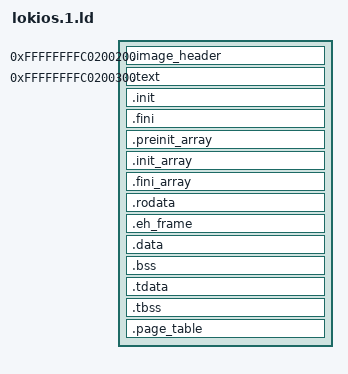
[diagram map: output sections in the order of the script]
SECTIONS
{
    /* This value should match the _kernel_base value in lokios.0.ld. */
    _phys_addr = 0x00200200;
    _virt_addr = 0xFFFFFFFFC0000000 + _phys_addr;
    . = _virt_addr;
    .image_header :
    {
        LONG(_num_sectors)
        LONG(_page_table)
    }

    . = _virt_addr + 0x100;
    .text :
    {
        *lokios.1/entry.o(.text)
        *crtbeginS.o(.text)
        *lokios.1/init.o(.text)
        *(.text)
        *crtendS.o(.text)
    }

    .init :
    {
        *lokios.1/crti.o(.init)
        KEEP (*(SORT_NONE(.init)))
        *lokios.1/crtn.o(.init)
    }

    .fini :
    {
        *lokios.1/crti.o(.fini)
        KEEP (*(SORT_NONE(.fini)))
        *lokios.1/crtn.o(.fini)
    }

    .preinit_array :
    {
        PROVIDE_HIDDEN (__preinit_array_start = .);
        KEEP (*(.preinit_array))
        PROVIDE_HIDDEN (__preinit_array_end = .);
    }

    .init_array :
    {
        PROVIDE_HIDDEN (__init_array_start = .);
        KEEP (*(SORT_BY_INIT_PRIORITY(.init_array.*) \
                SORT_BY_INIT_PRIORITY(.ctors.*)))
        KEEP (*(.init_array \
                EXCLUDE_FILE (*crtbegin.o *crtbegin?.o *crtend.o *crtend?.o ) \
                .ctors))
        PROVIDE_HIDDEN (__init_array_end = .);
    }

    .fini_array :
    {
        PROVIDE_HIDDEN (__fini_array_start = .);
        KEEP (*(SORT_BY_INIT_PRIORITY(.fini_array.*) \
                SORT_BY_INIT_PRIORITY(.dtors.*)))
        KEEP (*(.fini_array \
                EXCLUDE_FILE (*crtbegin.o *crtbegin?.o *crtend.o *crtend?.o ) \
                .dtors))
        PROVIDE_HIDDEN (__fini_array_end = .);
    }

    .rodata :
    {
        *(.rodata)
    }

    .eh_frame :
    {
        _eh_frame_begin = .;
        *(.eh_frame)
        QUAD(0);
    }
    
    .data :
    {
        *(.data)
    }

    .bss :
    {
        *(.bss)
    }

    .tdata :
    {
        _tdata_begin = .;
        *(.tdata .tdata.* .gnu.linkonce.td.*)
        _tdata_end = .;
    }
    _tdata_size = SIZEOF(.tdata);

    .tbss :
    {
        _tbss_begin = .;
        *(.tbss .tbss.* .gnu.linkonce.tb.*)
        *(.tcommon)
        _tbss_end = .;
    }
    _tbss_size = ALIGN(SIZEOF(.tbss), ALIGNOF(.tdata));
    ASSERT(_tdata_size + _tbss_size < 0x0800, "TLS size overflow!")

    /* Provide a page table that identity-maps the first 64M of memory via 4K
     * and 2M pages. */
    . = ALIGN(4096);
    .page_table :
    {
        ASSERT(. == ALIGN(4096), "page table misaligned");
        _page_table = . - _virt_addr + _phys_addr;

        /* _page_table + 0x0000 */
        QUAD((_page_table + 0x1000) | 0x0000000000000003);/*0x0000000000000000*/
        QUAD(0);                                          /*0x0000008000000000*/
        QUAD(0);                                          /*0x0000010000000000*/
        QUAD(0);                                          /*0x0000018000000000*/
        QUAD(0);                                          /*0x0000020000000000*/
        QUAD(0);                                          /*0x0000028000000000*/
        QUAD(0);                                          /*0x0000030000000000*/
        QUAD(0);                                          /*0x0000038000000000*/
        QUAD(0);                                          /*0x0000040000000000*/
        QUAD(0);                                          /*0x0000048000000000*/
        QUAD(0);                                          /*0x0000050000000000*/
        QUAD(0);                                          /*0x0000058000000000*/
        QUAD(0);                                          /*0x0000060000000000*/
        QUAD(0);                                          /*0x0000068000000000*/
        QUAD(0);                                          /*0x0000070000000000*/
        QUAD(0);                                          /*0x0000078000000000*/
        QUAD(0);                                          /*0x0000080000000000*/
        QUAD(0);                                          /*0x0000088000000000*/
        QUAD(0);                                          /*0x0000090000000000*/
        QUAD(0);                                          /*0x0000098000000000*/
        QUAD(0);                                          /*0x00000A0000000000*/
        QUAD(0);                                          /*0x00000A8000000000*/
        QUAD(0);                                          /*0x00000B0000000000*/
        QUAD(0);                                          /*0x00000B8000000000*/
        QUAD(0);                                          /*0x00000C0000000000*/
        QUAD(0);                                          /*0x00000C8000000000*/
        QUAD(0);                                          /*0x00000D0000000000*/
        QUAD(0);                                          /*0x00000D8000000000*/
        QUAD(0);                                          /*0x00000E0000000000*/
        QUAD(0);                                          /*0x00000E8000000000*/
        QUAD(0);                                          /*0x00000F0000000000*/
        QUAD(0);                                          /*0x00000F8000000000*/
        QUAD(0);                                          /*0x0000100000000000*/
        QUAD(0);                                          /*0x0000108000000000*/
        QUAD(0);                                          /*0x0000110000000000*/
        QUAD(0);                                          /*0x0000118000000000*/
        QUAD(0);                                          /*0x0000120000000000*/
        QUAD(0);                                          /*0x0000128000000000*/
        QUAD(0);                                          /*0x0000130000000000*/
        QUAD(0);                                          /*0x0000138000000000*/
        QUAD(0);                                          /*0x0000140000000000*/
        QUAD(0);                                          /*0x0000148000000000*/
        QUAD(0);                                          /*0x0000150000000000*/
        QUAD(0);                                          /*0x0000158000000000*/
        QUAD(0);                                          /*0x0000160000000000*/
        QUAD(0);                                          /*0x0000168000000000*/
        QUAD(0);                                          /*0x0000170000000000*/
        QUAD(0);                                          /*0x0000178000000000*/
        QUAD(0);                                          /*0x0000180000000000*/
        QUAD(0);                                          /*0x0000188000000000*/
        QUAD(0);                                          /*0x0000190000000000*/
        QUAD(0);                                          /*0x0000198000000000*/
        QUAD(0);                                          /*0x00001A0000000000*/
        QUAD(0);                                          /*0x00001A8000000000*/
        QUAD(0);                                          /*0x00001B0000000000*/
        QUAD(0);                                          /*0x00001B8000000000*/
        QUAD(0);                                          /*0x00001C0000000000*/
        QUAD(0);                                          /*0x00001C8000000000*/
        QUAD(0);                                          /*0x00001D0000000000*/
        QUAD(0);                                          /*0x00001D8000000000*/
        QUAD(0);                                          /*0x00001E0000000000*/
        QUAD(0);                                          /*0x00001E8000000000*/
        QUAD(0);                                          /*0x00001F0000000000*/
        QUAD(0);                                          /*0x00001F8000000000*/
        QUAD(0);                                          /*0x0000200000000000*/
        QUAD(0);                                          /*0x0000208000000000*/
        QUAD(0);                                          /*0x0000210000000000*/
        QUAD(0);                                          /*0x0000218000000000*/
        QUAD(0);                                          /*0x0000220000000000*/
        QUAD(0);                                          /*0x0000228000000000*/
        QUAD(0);                                          /*0x0000230000000000*/
        QUAD(0);                                          /*0x0000238000000000*/
        QUAD(0);                                          /*0x0000240000000000*/
        QUAD(0);                                          /*0x0000248000000000*/
        QUAD(0);                                          /*0x0000250000000000*/
        QUAD(0);                                          /*0x0000258000000000*/
        QUAD(0);                                          /*0x0000260000000000*/
        QUAD(0);                                          /*0x0000268000000000*/
        QUAD(0);                                          /*0x0000270000000000*/
        QUAD(0);                                          /*0x0000278000000000*/
        QUAD(0);                                          /*0x0000280000000000*/
        QUAD(0);                                          /*0x0000288000000000*/
        QUAD(0);                                          /*0x0000290000000000*/
        QUAD(0);                                          /*0x0000298000000000*/
        QUAD(0);                                          /*0x00002A0000000000*/
        QUAD(0);                                          /*0x00002A8000000000*/
        QUAD(0);                                          /*0x00002B0000000000*/
        QUAD(0);                                          /*0x00002B8000000000*/
        QUAD(0);                                          /*0x00002C0000000000*/
        QUAD(0);                                          /*0x00002C8000000000*/
        QUAD(0);                                          /*0x00002D0000000000*/
        QUAD(0);                                          /*0x00002D8000000000*/
        QUAD(0);                                          /*0x00002E0000000000*/
        QUAD(0);                                          /*0x00002E8000000000*/
        QUAD(0);                                          /*0x00002F0000000000*/
        QUAD(0);                                          /*0x00002F8000000000*/
        QUAD(0);                                          /*0x0000300000000000*/
        QUAD(0);                                          /*0x0000308000000000*/
        QUAD(0);                                          /*0x0000310000000000*/
        QUAD(0);                                          /*0x0000318000000000*/
        QUAD(0);                                          /*0x0000320000000000*/
        QUAD(0);                                          /*0x0000328000000000*/
        QUAD(0);                                          /*0x0000330000000000*/
        QUAD(0);                                          /*0x0000338000000000*/
        QUAD(0);                                          /*0x0000340000000000*/
        QUAD(0);                                          /*0x0000348000000000*/
        QUAD(0);                                          /*0x0000350000000000*/
        QUAD(0);                                          /*0x0000358000000000*/
        QUAD(0);                                          /*0x0000360000000000*/
        QUAD(0);                                          /*0x0000368000000000*/
        QUAD(0);                                          /*0x0000370000000000*/
        QUAD(0);                                          /*0x0000378000000000*/
        QUAD(0);                                          /*0x0000380000000000*/
        QUAD(0);                                          /*0x0000388000000000*/
        QUAD(0);                                          /*0x0000390000000000*/
        QUAD(0);                                          /*0x0000398000000000*/
        QUAD(0);                                          /*0x00003A0000000000*/
        QUAD(0);                                          /*0x00003A8000000000*/
        QUAD(0);                                          /*0x00003B0000000000*/
        QUAD(0);                                          /*0x00003B8000000000*/
        QUAD(0);                                          /*0x00003C0000000000*/
        QUAD(0);                                          /*0x00003C8000000000*/
        QUAD(0);                                          /*0x00003D0000000000*/
        QUAD(0);                                          /*0x00003D8000000000*/
        QUAD(0);                                          /*0x00003E0000000000*/
        QUAD(0);                                          /*0x00003E8000000000*/
        QUAD(0);                                          /*0x00003F0000000000*/
        QUAD(0);                                          /*0x00003F8000000000*/
        QUAD(0);                                          /*0x0000400000000000*/
        QUAD(0);                                          /*0x0000408000000000*/
        QUAD(0);                                          /*0x0000410000000000*/
        QUAD(0);                                          /*0x0000418000000000*/
        QUAD(0);                                          /*0x0000420000000000*/
        QUAD(0);                                          /*0x0000428000000000*/
        QUAD(0);                                          /*0x0000430000000000*/
        QUAD(0);                                          /*0x0000438000000000*/
        QUAD(0);                                          /*0x0000440000000000*/
        QUAD(0);                                          /*0x0000448000000000*/
        QUAD(0);                                          /*0x0000450000000000*/
        QUAD(0);                                          /*0x0000458000000000*/
        QUAD(0);                                          /*0x0000460000000000*/
        QUAD(0);                                          /*0x0000468000000000*/
        QUAD(0);                                          /*0x0000470000000000*/
        QUAD(0);                                          /*0x0000478000000000*/
        QUAD(0);                                          /*0x0000480000000000*/
        QUAD(0);                                          /*0x0000488000000000*/
        QUAD(0);                                          /*0x0000490000000000*/
        QUAD(0);                                          /*0x0000498000000000*/
        QUAD(0);                                          /*0x00004A0000000000*/
        QUAD(0);                                          /*0x00004A8000000000*/
        QUAD(0);                                          /*0x00004B0000000000*/
        QUAD(0);                                          /*0x00004B8000000000*/
        QUAD(0);                                          /*0x00004C0000000000*/
        QUAD(0);                                          /*0x00004C8000000000*/
        QUAD(0);                                          /*0x00004D0000000000*/
        QUAD(0);                                          /*0x00004D8000000000*/
        QUAD(0);                                          /*0x00004E0000000000*/
        QUAD(0);                                          /*0x00004E8000000000*/
        QUAD(0);                                          /*0x00004F0000000000*/
        QUAD(0);                                          /*0x00004F8000000000*/
        QUAD(0);                                          /*0x0000500000000000*/
        QUAD(0);                                          /*0x0000508000000000*/
        QUAD(0);                                          /*0x0000510000000000*/
        QUAD(0);                                          /*0x0000518000000000*/
        QUAD(0);                                          /*0x0000520000000000*/
        QUAD(0);                                          /*0x0000528000000000*/
        QUAD(0);                                          /*0x0000530000000000*/
        QUAD(0);                                          /*0x0000538000000000*/
        QUAD(0);                                          /*0x0000540000000000*/
        QUAD(0);                                          /*0x0000548000000000*/
        QUAD(0);                                          /*0x0000550000000000*/
        QUAD(0);                                          /*0x0000558000000000*/
        QUAD(0);                                          /*0x0000560000000000*/
        QUAD(0);                                          /*0x0000568000000000*/
        QUAD(0);                                          /*0x0000570000000000*/
        QUAD(0);                                          /*0x0000578000000000*/
        QUAD(0);                                          /*0x0000580000000000*/
        QUAD(0);                                          /*0x0000588000000000*/
        QUAD(0);                                          /*0x0000590000000000*/
        QUAD(0);                                          /*0x0000598000000000*/
        QUAD(0);                                          /*0x00005A0000000000*/
        QUAD(0);                                          /*0x00005A8000000000*/
        QUAD(0);                                          /*0x00005B0000000000*/
        QUAD(0);                                          /*0x00005B8000000000*/
        QUAD(0);                                          /*0x00005C0000000000*/
        QUAD(0);                                          /*0x00005C8000000000*/
        QUAD(0);                                          /*0x00005D0000000000*/
        QUAD(0);                                          /*0x00005D8000000000*/
        QUAD(0);                                          /*0x00005E0000000000*/
        QUAD(0);                                          /*0x00005E8000000000*/
        QUAD(0);                                          /*0x00005F0000000000*/
        QUAD(0);                                          /*0x00005F8000000000*/
        QUAD(0);                                          /*0x0000600000000000*/
        QUAD(0);                                          /*0x0000608000000000*/
        QUAD(0);                                          /*0x0000610000000000*/
        QUAD(0);                                          /*0x0000618000000000*/
        QUAD(0);                                          /*0x0000620000000000*/
        QUAD(0);                                          /*0x0000628000000000*/
        QUAD(0);                                          /*0x0000630000000000*/
        QUAD(0);                                          /*0x0000638000000000*/
        QUAD(0);                                          /*0x0000640000000000*/
        QUAD(0);                                          /*0x0000648000000000*/
        QUAD(0);                                          /*0x0000650000000000*/
        QUAD(0);                                          /*0x0000658000000000*/
        QUAD(0);                                          /*0x0000660000000000*/
        QUAD(0);                                          /*0x0000668000000000*/
        QUAD(0);                                          /*0x0000670000000000*/
        QUAD(0);                                          /*0x0000678000000000*/
        QUAD(0);                                          /*0x0000680000000000*/
        QUAD(0);                                          /*0x0000688000000000*/
        QUAD(0);                                          /*0x0000690000000000*/
        QUAD(0);                                          /*0x0000698000000000*/
        QUAD(0);                                          /*0x00006A0000000000*/
        QUAD(0);                                          /*0x00006A8000000000*/
        QUAD(0);                                          /*0x00006B0000000000*/
        QUAD(0);                                          /*0x00006B8000000000*/
        QUAD(0);                                          /*0x00006C0000000000*/
        QUAD(0);                                          /*0x00006C8000000000*/
        QUAD(0);                                          /*0x00006D0000000000*/
        QUAD(0);                                          /*0x00006D8000000000*/
        QUAD(0);                                          /*0x00006E0000000000*/
        QUAD(0);                                          /*0x00006E8000000000*/
        QUAD(0);                                          /*0x00006F0000000000*/
        QUAD(0);                                          /*0x00006F8000000000*/
        QUAD(0);                                          /*0x0000700000000000*/
        QUAD(0);                                          /*0x0000708000000000*/
        QUAD(0);                                          /*0x0000710000000000*/
        QUAD(0);                                          /*0x0000718000000000*/
        QUAD(0);                                          /*0x0000720000000000*/
        QUAD(0);                                          /*0x0000728000000000*/
        QUAD(0);                                          /*0x0000730000000000*/
        QUAD(0);                                          /*0x0000738000000000*/
        QUAD(0);                                          /*0x0000740000000000*/
        QUAD(0);                                          /*0x0000748000000000*/
        QUAD(0);                                          /*0x0000750000000000*/
        QUAD(0);                                          /*0x0000758000000000*/
        QUAD(0);                                          /*0x0000760000000000*/
        QUAD(0);                                          /*0x0000768000000000*/
        QUAD(0);                                          /*0x0000770000000000*/
        QUAD(0);                                          /*0x0000778000000000*/
        QUAD(0);                                          /*0x0000780000000000*/
        QUAD(0);                                          /*0x0000788000000000*/
        QUAD(0);                                          /*0x0000790000000000*/
        QUAD(0);                                          /*0x0000798000000000*/
        QUAD(0);                                          /*0x00007A0000000000*/
        QUAD(0);                                          /*0x00007A8000000000*/
        QUAD(0);                                          /*0x00007B0000000000*/
        QUAD(0);                                          /*0x00007B8000000000*/
        QUAD(0);                                          /*0x00007C0000000000*/
        QUAD(0);                                          /*0x00007C8000000000*/
        QUAD(0);                                          /*0x00007D0000000000*/
        QUAD(0);                                          /*0x00007D8000000000*/
        QUAD(0);                                          /*0x00007E0000000000*/
        QUAD(0);                                          /*0x00007E8000000000*/
        QUAD(0);                                          /*0x00007F0000000000*/
        QUAD(0);                                          /*0x00007F8000000000*/
        QUAD((_page_table + 0x1000) | 0x0000000000000003);/*0xFFFF800000000000*/
        QUAD(0);                                          /*0xFFFF808000000000*/
        QUAD(0);                                          /*0xFFFF810000000000*/
        QUAD(0);                                          /*0xFFFF818000000000*/
        QUAD(0);                                          /*0xFFFF820000000000*/
        QUAD(0);                                          /*0xFFFF828000000000*/
        QUAD(0);                                          /*0xFFFF830000000000*/
        QUAD(0);                                          /*0xFFFF838000000000*/
        QUAD(0);                                          /*0xFFFF840000000000*/
        QUAD(0);                                          /*0xFFFF848000000000*/
        QUAD(0);                                          /*0xFFFF850000000000*/
        QUAD(0);                                          /*0xFFFF858000000000*/
        QUAD(0);                                          /*0xFFFF860000000000*/
        QUAD(0);                                          /*0xFFFF868000000000*/
        QUAD(0);                                          /*0xFFFF870000000000*/
        QUAD(0);                                          /*0xFFFF878000000000*/
        QUAD(0);                                          /*0xFFFF880000000000*/
        QUAD(0);                                          /*0xFFFF888000000000*/
        QUAD(0);                                          /*0xFFFF890000000000*/
        QUAD(0);                                          /*0xFFFF898000000000*/
        QUAD(0);                                          /*0xFFFF8A0000000000*/
        QUAD(0);                                          /*0xFFFF8A8000000000*/
        QUAD(0);                                          /*0xFFFF8B0000000000*/
        QUAD(0);                                          /*0xFFFF8B8000000000*/
        QUAD(0);                                          /*0xFFFF8C0000000000*/
        QUAD(0);                                          /*0xFFFF8C8000000000*/
        QUAD(0);                                          /*0xFFFF8D0000000000*/
        QUAD(0);                                          /*0xFFFF8D8000000000*/
        QUAD(0);                                          /*0xFFFF8E0000000000*/
        QUAD(0);                                          /*0xFFFF8E8000000000*/
        QUAD(0);                                          /*0xFFFF8F0000000000*/
        QUAD(0);                                          /*0xFFFF8F8000000000*/
        QUAD(0);                                          /*0xFFFF900000000000*/
        QUAD(0);                                          /*0xFFFF908000000000*/
        QUAD(0);                                          /*0xFFFF910000000000*/
        QUAD(0);                                          /*0xFFFF918000000000*/
        QUAD(0);                                          /*0xFFFF920000000000*/
        QUAD(0);                                          /*0xFFFF928000000000*/
        QUAD(0);                                          /*0xFFFF930000000000*/
        QUAD(0);                                          /*0xFFFF938000000000*/
        QUAD(0);                                          /*0xFFFF940000000000*/
        QUAD(0);                                          /*0xFFFF948000000000*/
        QUAD(0);                                          /*0xFFFF950000000000*/
        QUAD(0);                                          /*0xFFFF958000000000*/
        QUAD(0);                                          /*0xFFFF960000000000*/
        QUAD(0);                                          /*0xFFFF968000000000*/
        QUAD(0);                                          /*0xFFFF970000000000*/
        QUAD(0);                                          /*0xFFFF978000000000*/
        QUAD(0);                                          /*0xFFFF980000000000*/
        QUAD(0);                                          /*0xFFFF988000000000*/
        QUAD(0);                                          /*0xFFFF990000000000*/
        QUAD(0);                                          /*0xFFFF998000000000*/
        QUAD(0);                                          /*0xFFFF9A0000000000*/
        QUAD(0);                                          /*0xFFFF9A8000000000*/
        QUAD(0);                                          /*0xFFFF9B0000000000*/
        QUAD(0);                                          /*0xFFFF9B8000000000*/
        QUAD(0);                                          /*0xFFFF9C0000000000*/
        QUAD(0);                                          /*0xFFFF9C8000000000*/
        QUAD(0);                                          /*0xFFFF9D0000000000*/
        QUAD(0);                                          /*0xFFFF9D8000000000*/
        QUAD(0);                                          /*0xFFFF9E0000000000*/
        QUAD(0);                                          /*0xFFFF9E8000000000*/
        QUAD(0);                                          /*0xFFFF9F0000000000*/
        QUAD(0);                                          /*0xFFFF9F8000000000*/
        QUAD(0);                                          /*0xFFFFA00000000000*/
        QUAD(0);                                          /*0xFFFFA08000000000*/
        QUAD(0);                                          /*0xFFFFA10000000000*/
        QUAD(0);                                          /*0xFFFFA18000000000*/
        QUAD(0);                                          /*0xFFFFA20000000000*/
        QUAD(0);                                          /*0xFFFFA28000000000*/
        QUAD(0);                                          /*0xFFFFA30000000000*/
        QUAD(0);                                          /*0xFFFFA38000000000*/
        QUAD(0);                                          /*0xFFFFA40000000000*/
        QUAD(0);                                          /*0xFFFFA48000000000*/
        QUAD(0);                                          /*0xFFFFA50000000000*/
        QUAD(0);                                          /*0xFFFFA58000000000*/
        QUAD(0);                                          /*0xFFFFA60000000000*/
        QUAD(0);                                          /*0xFFFFA68000000000*/
        QUAD(0);                                          /*0xFFFFA70000000000*/
        QUAD(0);                                          /*0xFFFFA78000000000*/
        QUAD(0);                                          /*0xFFFFA80000000000*/
        QUAD(0);                                          /*0xFFFFA88000000000*/
        QUAD(0);                                          /*0xFFFFA90000000000*/
        QUAD(0);                                          /*0xFFFFA98000000000*/
        QUAD(0);                                          /*0xFFFFAA0000000000*/
        QUAD(0);                                          /*0xFFFFAA8000000000*/
        QUAD(0);                                          /*0xFFFFAB0000000000*/
        QUAD(0);                                          /*0xFFFFAB8000000000*/
        QUAD(0);                                          /*0xFFFFAC0000000000*/
        QUAD(0);                                          /*0xFFFFAC8000000000*/
        QUAD(0);                                          /*0xFFFFAD0000000000*/
        QUAD(0);                                          /*0xFFFFAD8000000000*/
        QUAD(0);                                          /*0xFFFFAE0000000000*/
        QUAD(0);                                          /*0xFFFFAE8000000000*/
        QUAD(0);                                          /*0xFFFFAF0000000000*/
        QUAD(0);                                          /*0xFFFFAF8000000000*/
        QUAD(0);                                          /*0xFFFFB00000000000*/
        QUAD(0);                                          /*0xFFFFB08000000000*/
        QUAD(0);                                          /*0xFFFFB10000000000*/
        QUAD(0);                                          /*0xFFFFB18000000000*/
        QUAD(0);                                          /*0xFFFFB20000000000*/
        QUAD(0);                                          /*0xFFFFB28000000000*/
        QUAD(0);                                          /*0xFFFFB30000000000*/
        QUAD(0);                                          /*0xFFFFB38000000000*/
        QUAD(0);                                          /*0xFFFFB40000000000*/
        QUAD(0);                                          /*0xFFFFB48000000000*/
        QUAD(0);                                          /*0xFFFFB50000000000*/
        QUAD(0);                                          /*0xFFFFB58000000000*/
        QUAD(0);                                          /*0xFFFFB60000000000*/
        QUAD(0);                                          /*0xFFFFB68000000000*/
        QUAD(0);                                          /*0xFFFFB70000000000*/
        QUAD(0);                                          /*0xFFFFB78000000000*/
        QUAD(0);                                          /*0xFFFFB80000000000*/
        QUAD(0);                                          /*0xFFFFB88000000000*/
        QUAD(0);                                          /*0xFFFFB90000000000*/
        QUAD(0);                                          /*0xFFFFB98000000000*/
        QUAD(0);                                          /*0xFFFFBA0000000000*/
        QUAD(0);                                          /*0xFFFFBA8000000000*/
        QUAD(0);                                          /*0xFFFFBB0000000000*/
        QUAD(0);                                          /*0xFFFFBB8000000000*/
        QUAD(0);                                          /*0xFFFFBC0000000000*/
        QUAD(0);                                          /*0xFFFFBC8000000000*/
        QUAD(0);                                          /*0xFFFFBD0000000000*/
        QUAD(0);                                          /*0xFFFFBD8000000000*/
        QUAD(0);                                          /*0xFFFFBE0000000000*/
        QUAD(0);                                          /*0xFFFFBE8000000000*/
        QUAD(0);                                          /*0xFFFFBF0000000000*/
        QUAD(0);                                          /*0xFFFFBF8000000000*/
        QUAD(0);                                          /*0xFFFFC00000000000*/
        QUAD(0);                                          /*0xFFFFC08000000000*/
        QUAD(0);                                          /*0xFFFFC10000000000*/
        QUAD(0);                                          /*0xFFFFC18000000000*/
        QUAD(0);                                          /*0xFFFFC20000000000*/
        QUAD(0);                                          /*0xFFFFC28000000000*/
        QUAD(0);                                          /*0xFFFFC30000000000*/
        QUAD(0);                                          /*0xFFFFC38000000000*/
        QUAD(0);                                          /*0xFFFFC40000000000*/
        QUAD(0);                                          /*0xFFFFC48000000000*/
        QUAD(0);                                          /*0xFFFFC50000000000*/
        QUAD(0);                                          /*0xFFFFC58000000000*/
        QUAD(0);                                          /*0xFFFFC60000000000*/
        QUAD(0);                                          /*0xFFFFC68000000000*/
        QUAD(0);                                          /*0xFFFFC70000000000*/
        QUAD(0);                                          /*0xFFFFC78000000000*/
        QUAD(0);                                          /*0xFFFFC80000000000*/
        QUAD(0);                                          /*0xFFFFC88000000000*/
        QUAD(0);                                          /*0xFFFFC90000000000*/
        QUAD(0);                                          /*0xFFFFC98000000000*/
        QUAD(0);                                          /*0xFFFFCA0000000000*/
        QUAD(0);                                          /*0xFFFFCA8000000000*/
        QUAD(0);                                          /*0xFFFFCB0000000000*/
        QUAD(0);                                          /*0xFFFFCB8000000000*/
        QUAD(0);                                          /*0xFFFFCC0000000000*/
        QUAD(0);                                          /*0xFFFFCC8000000000*/
        QUAD(0);                                          /*0xFFFFCD0000000000*/
        QUAD(0);                                          /*0xFFFFCD8000000000*/
        QUAD(0);                                          /*0xFFFFCE0000000000*/
        QUAD(0);                                          /*0xFFFFCE8000000000*/
        QUAD(0);                                          /*0xFFFFCF0000000000*/
        QUAD(0);                                          /*0xFFFFCF8000000000*/
        QUAD(0);                                          /*0xFFFFD00000000000*/
        QUAD(0);                                          /*0xFFFFD08000000000*/
        QUAD(0);                                          /*0xFFFFD10000000000*/
        QUAD(0);                                          /*0xFFFFD18000000000*/
        QUAD(0);                                          /*0xFFFFD20000000000*/
        QUAD(0);                                          /*0xFFFFD28000000000*/
        QUAD(0);                                          /*0xFFFFD30000000000*/
        QUAD(0);                                          /*0xFFFFD38000000000*/
        QUAD(0);                                          /*0xFFFFD40000000000*/
        QUAD(0);                                          /*0xFFFFD48000000000*/
        QUAD(0);                                          /*0xFFFFD50000000000*/
        QUAD(0);                                          /*0xFFFFD58000000000*/
        QUAD(0);                                          /*0xFFFFD60000000000*/
        QUAD(0);                                          /*0xFFFFD68000000000*/
        QUAD(0);                                          /*0xFFFFD70000000000*/
        QUAD(0);                                          /*0xFFFFD78000000000*/
        QUAD(0);                                          /*0xFFFFD80000000000*/
        QUAD(0);                                          /*0xFFFFD88000000000*/
        QUAD(0);                                          /*0xFFFFD90000000000*/
        QUAD(0);                                          /*0xFFFFD98000000000*/
        QUAD(0);                                          /*0xFFFFDA0000000000*/
        QUAD(0);                                          /*0xFFFFDA8000000000*/
        QUAD(0);                                          /*0xFFFFDB0000000000*/
        QUAD(0);                                          /*0xFFFFDB8000000000*/
        QUAD(0);                                          /*0xFFFFDC0000000000*/
        QUAD(0);                                          /*0xFFFFDC8000000000*/
        QUAD(0);                                          /*0xFFFFDD0000000000*/
        QUAD(0);                                          /*0xFFFFDD8000000000*/
        QUAD(0);                                          /*0xFFFFDE0000000000*/
        QUAD(0);                                          /*0xFFFFDE8000000000*/
        QUAD(0);                                          /*0xFFFFDF0000000000*/
        QUAD(0);                                          /*0xFFFFDF8000000000*/
        QUAD(0);                                          /*0xFFFFE00000000000*/
        QUAD(0);                                          /*0xFFFFE08000000000*/
        QUAD(0);                                          /*0xFFFFE10000000000*/
        QUAD(0);                                          /*0xFFFFE18000000000*/
        QUAD(0);                                          /*0xFFFFE20000000000*/
        QUAD(0);                                          /*0xFFFFE28000000000*/
        QUAD(0);                                          /*0xFFFFE30000000000*/
        QUAD(0);                                          /*0xFFFFE38000000000*/
        QUAD(0);                                          /*0xFFFFE40000000000*/
        QUAD(0);                                          /*0xFFFFE48000000000*/
        QUAD(0);                                          /*0xFFFFE50000000000*/
        QUAD(0);                                          /*0xFFFFE58000000000*/
        QUAD(0);                                          /*0xFFFFE60000000000*/
        QUAD(0);                                          /*0xFFFFE68000000000*/
        QUAD(0);                                          /*0xFFFFE70000000000*/
        QUAD(0);                                          /*0xFFFFE78000000000*/
        QUAD(0);                                          /*0xFFFFE80000000000*/
        QUAD(0);                                          /*0xFFFFE88000000000*/
        QUAD(0);                                          /*0xFFFFE90000000000*/
        QUAD(0);                                          /*0xFFFFE98000000000*/
        QUAD(0);                                          /*0xFFFFEA0000000000*/
        QUAD(0);                                          /*0xFFFFEA8000000000*/
        QUAD(0);                                          /*0xFFFFEB0000000000*/
        QUAD(0);                                          /*0xFFFFEB8000000000*/
        QUAD(0);                                          /*0xFFFFEC0000000000*/
        QUAD(0);                                          /*0xFFFFEC8000000000*/
        QUAD(0);                                          /*0xFFFFED0000000000*/
        QUAD(0);                                          /*0xFFFFED8000000000*/
        QUAD(0);                                          /*0xFFFFEE0000000000*/
        QUAD(0);                                          /*0xFFFFEE8000000000*/
        QUAD(0);                                          /*0xFFFFEF0000000000*/
        QUAD(0);                                          /*0xFFFFEF8000000000*/
        QUAD(0);                                          /*0xFFFFF00000000000*/
        QUAD(0);                                          /*0xFFFFF08000000000*/
        QUAD(0);                                          /*0xFFFFF10000000000*/
        QUAD(0);                                          /*0xFFFFF18000000000*/
        QUAD(0);                                          /*0xFFFFF20000000000*/
        QUAD(0);                                          /*0xFFFFF28000000000*/
        QUAD(0);                                          /*0xFFFFF30000000000*/
        QUAD(0);                                          /*0xFFFFF38000000000*/
        QUAD(0);                                          /*0xFFFFF40000000000*/
        QUAD(0);                                          /*0xFFFFF48000000000*/
        QUAD(0);                                          /*0xFFFFF50000000000*/
        QUAD(0);                                          /*0xFFFFF58000000000*/
        QUAD(0);                                          /*0xFFFFF60000000000*/
        QUAD(0);                                          /*0xFFFFF68000000000*/
        QUAD(0);                                          /*0xFFFFF70000000000*/
        QUAD(0);                                          /*0xFFFFF78000000000*/
        QUAD(0);                                          /*0xFFFFF80000000000*/
        QUAD(0);                                          /*0xFFFFF88000000000*/
        QUAD(0);                                          /*0xFFFFF90000000000*/
        QUAD(0);                                          /*0xFFFFF98000000000*/
        QUAD(0);                                          /*0xFFFFFA0000000000*/
        QUAD(0);                                          /*0xFFFFFA8000000000*/
        QUAD(0);                                          /*0xFFFFFB0000000000*/
        QUAD(0);                                          /*0xFFFFFB8000000000*/
        QUAD(0);                                          /*0xFFFFFC0000000000*/
        QUAD(0);                                          /*0xFFFFFC8000000000*/
        QUAD(0);                                          /*0xFFFFFD0000000000*/
        QUAD(0);                                          /*0xFFFFFD8000000000*/
        QUAD(0);                                          /*0xFFFFFE0000000000*/
        QUAD(0);                                          /*0xFFFFFE8000000000*/
        QUAD(0);                                          /*0xFFFFFF0000000000*/
        QUAD((_page_table + 0x4000) | 0x0000000000000003);/*0xFFFFFF8000000000*/

        /* _page_table + 0x1000 */
        . = ALIGN(4096);
        QUAD((_page_table + 0x2000) | 0x1000000000000003);/*0x-----00000000000*/

        /* _page_table + 0x2000 */
        . = ALIGN(4096);
        QUAD((_page_table + 0x3000) | 0x2000000000000003);/*0x-----00000000000*/
        QUAD(0x2000000000200083);                         /*0x-----00000200000*/
        QUAD(0x2000000000400083);                         /*0x-----00000400000*/
        QUAD(0x2000000000600083);                         /*0x-----00000600000*/
        QUAD(0x2000000000800083);                         /*0x-----00000800000*/
        QUAD(0x2000000000A00083);                         /*0x-----00000A00000*/
        QUAD(0x2000000000C00083);                         /*0x-----00000C00000*/
        QUAD(0x2000000000E00083);                         /*0x-----00000E00000*/

        /* _page_table + 0x3000 */
        . = ALIGN(4096);
        QUAD(0x3000000000000081);
        QUAD(0x3000000000001081);
        QUAD(0x3000000000002081);
        QUAD(0x3000000000003081);
        QUAD(0x3000000000004081);
        QUAD(0x3000000000005081);
        QUAD(0x3000000000006081);
        QUAD(0x3000000000007081);
        QUAD(0x3000000000008081);
        QUAD(0x3000000000009081);
        QUAD(0x300000000000A081);
        QUAD(0x300000000000B081);
        QUAD(0x300000000000C081);
        QUAD(0x300000000000D081);
        QUAD(0x300000000000E081);
        QUAD(0x300000000000F081);
        QUAD(0x3000000000010081);
        QUAD(0x3000000000011081);
        QUAD(0x3000000000012081);
        QUAD(0x3000000000013081);
        QUAD(0x3000000000014081);
        QUAD(0x3000000000015081);
        QUAD(0x3000000000016081);
        QUAD(0x3000000000017081);
        QUAD(0x3000000000018081);
        QUAD(0x3000000000019081);
        QUAD(0x300000000001A081);
        QUAD(0x300000000001B081);
        QUAD(0x300000000001C081);
        QUAD(0x300000000001D081);
        QUAD(0x300000000001E081);
        QUAD(0x300000000001F081);
        QUAD(0x3000000000020081);
        QUAD(0x3000000000021081);
        QUAD(0x3000000000022081);
        QUAD(0x3000000000023081);
        QUAD(0x3000000000024081);
        QUAD(0x3000000000025081);
        QUAD(0x3000000000026081);
        QUAD(0x3000000000027081);
        QUAD(0x3000000000028081);
        QUAD(0x3000000000029081);
        QUAD(0x300000000002A081);
        QUAD(0x300000000002B081);
        QUAD(0x300000000002C081);
        QUAD(0x300000000002D081);
        QUAD(0x300000000002E081);
        QUAD(0x300000000002F081);
        QUAD(0x3000000000030081);
        QUAD(0x3000000000031081);
        QUAD(0x3000000000032081);
        QUAD(0x3000000000033081);
        QUAD(0x3000000000034081);
        QUAD(0x3000000000035081);
        QUAD(0x3000000000036081);
        QUAD(0x3000000000037081);
        QUAD(0x3000000000038081);
        QUAD(0x3000000000039081);
        QUAD(0x300000000003A081);
        QUAD(0x300000000003B081);
        QUAD(0x300000000003C081);
        QUAD(0x300000000003D081);
        QUAD(0x300000000003E081);
        QUAD(0x300000000003F081);
        QUAD(0x3000000000040081);
        QUAD(0x3000000000041081);
        QUAD(0x3000000000042081);
        QUAD(0x3000000000043081);
        QUAD(0x3000000000044081);
        QUAD(0x3000000000045081);
        QUAD(0x3000000000046081);
        QUAD(0x3000000000047081);
        QUAD(0x3000000000048081);
        QUAD(0x3000000000049081);
        QUAD(0x300000000004A081);
        QUAD(0x300000000004B081);
        QUAD(0x300000000004C081);
        QUAD(0x300000000004D081);
        QUAD(0x300000000004E081);
        QUAD(0x300000000004F081);
        QUAD(0x3000000000050081);
        QUAD(0x3000000000051081);
        QUAD(0x3000000000052081);
        QUAD(0x3000000000053081);
        QUAD(0x3000000000054081);
        QUAD(0x3000000000055081);
        QUAD(0x3000000000056081);
        QUAD(0x3000000000057081);
        QUAD(0x3000000000058081);
        QUAD(0x3000000000059081);
        QUAD(0x300000000005A081);
        QUAD(0x300000000005B081);
        QUAD(0x300000000005C081);
        QUAD(0x300000000005D081);
        QUAD(0x300000000005E081);
        QUAD(0x300000000005F081);
        QUAD(0x3000000000060081);
        QUAD(0x3000000000061081);
        QUAD(0x3000000000062081);
        QUAD(0x3000000000063081);
        QUAD(0x3000000000064081);
        QUAD(0x3000000000065081);
        QUAD(0x3000000000066081);
        QUAD(0x3000000000067081);
        QUAD(0x3000000000068081);
        QUAD(0x3000000000069081);
        QUAD(0x300000000006A081);
        QUAD(0x300000000006B081);
        QUAD(0x300000000006C081);
        QUAD(0x300000000006D081);
        QUAD(0x300000000006E081);
        QUAD(0x300000000006F081);
        QUAD(0x3000000000070081);
        QUAD(0x3000000000071081);
        QUAD(0x3000000000072081);
        QUAD(0x3000000000073081);
        QUAD(0x3000000000074081);
        QUAD(0x3000000000075081);
        QUAD(0x3000000000076081);
        QUAD(0x3000000000077081);
        QUAD(0x3000000000078081);
        QUAD(0x3000000000079081);
        QUAD(0x300000000007A081);
        QUAD(0x300000000007B081);
        QUAD(0x300000000007C081);
        QUAD(0x300000000007D081);
        QUAD(0x300000000007E081);
        QUAD(0x300000000007F081);
        QUAD(0x3000000000080081);
        QUAD(0x3000000000081081);
        QUAD(0x3000000000082081);
        QUAD(0x3000000000083081);
        QUAD(0x3000000000084081);
        QUAD(0x3000000000085081);
        QUAD(0x3000000000086081);
        QUAD(0x3000000000087081);
        QUAD(0x3000000000088081);
        QUAD(0x3000000000089081);
        QUAD(0x300000000008A081);
        QUAD(0x300000000008B081);
        QUAD(0x300000000008C081);
        QUAD(0x300000000008D081);
        QUAD(0x300000000008E081);
        QUAD(0x300000000008F081);
        QUAD(0x3000000000090081);
        QUAD(0x3000000000091081);
        QUAD(0x3000000000092081);
        QUAD(0x3000000000093081);
        QUAD(0x3000000000094081);
        QUAD(0x3000000000095081);
        QUAD(0x3000000000096081);
        QUAD(0x3000000000097081);
        QUAD(0x3000000000098081);
        QUAD(0x3000000000099081);
        QUAD(0x300000000009A081);
        QUAD(0x300000000009B081);
        QUAD(0x300000000009C081);
        QUAD(0x300000000009D081);
        QUAD(0x300000000009E081);
        QUAD(0x300000000009F081);
        QUAD(0x30000000000A0081);
        QUAD(0x30000000000A1081);
        QUAD(0x30000000000A2081);
        QUAD(0x30000000000A3081);
        QUAD(0x30000000000A4081);
        QUAD(0x30000000000A5081);
        QUAD(0x30000000000A6081);
        QUAD(0x30000000000A7081);
        QUAD(0x30000000000A8081);
        QUAD(0x30000000000A9081);
        QUAD(0x30000000000AA081);
        QUAD(0x30000000000AB081);
        QUAD(0x30000000000AC081);
        QUAD(0x30000000000AD081);
        QUAD(0x30000000000AE081);
        QUAD(0x30000000000AF081);
        QUAD(0x30000000000B0081);
        QUAD(0x30000000000B1081);
        QUAD(0x30000000000B2081);
        QUAD(0x30000000000B3081);
        QUAD(0x30000000000B4081);
        QUAD(0x30000000000B5081);
        QUAD(0x30000000000B6081);
        QUAD(0x30000000000B7081);
        QUAD(0xB0000000000B8087); /* VRAM */
        QUAD(0xB0000000000B9087); /* VRAM */
        QUAD(0xB0000000000BA087); /* VRAM */
        QUAD(0xB0000000000BB087); /* VRAM */
        QUAD(0xB0000000000BC087); /* VRAM */
        QUAD(0xB0000000000BD087); /* VRAM */
        QUAD(0xB0000000000BE087); /* VRAM */
        QUAD(0xB0000000000BF087); /* VRAM */
        QUAD(0x30000000000C0081);
        QUAD(0x30000000000C1081);
        QUAD(0x30000000000C2081);
        QUAD(0x30000000000C3081);
        QUAD(0x30000000000C4081);
        QUAD(0x30000000000C5081);
        QUAD(0x30000000000C6081);
        QUAD(0x30000000000C7081);
        QUAD(0x30000000000C8081);
        QUAD(0x30000000000C9081);
        QUAD(0x30000000000CA081);
        QUAD(0x30000000000CB081);
        QUAD(0x30000000000CC081);
        QUAD(0x30000000000CD081);
        QUAD(0x30000000000CE081);
        QUAD(0x30000000000CF081);
        QUAD(0x30000000000D0081);
        QUAD(0x30000000000D1081);
        QUAD(0x30000000000D2081);
        QUAD(0x30000000000D3081);
        QUAD(0x30000000000D4081);
        QUAD(0x30000000000D5081);
        QUAD(0x30000000000D6081);
        QUAD(0x30000000000D7081);
        QUAD(0x30000000000D8081);
        QUAD(0x30000000000D9081);
        QUAD(0x30000000000DA081);
        QUAD(0x30000000000DB081);
        QUAD(0x30000000000DC081);
        QUAD(0x30000000000DD081);
        QUAD(0x30000000000DE081);
        QUAD(0x30000000000DF081);
        QUAD(0x30000000000E0081);
        QUAD(0x30000000000E1081);
        QUAD(0x30000000000E2081);
        QUAD(0x30000000000E3081);
        QUAD(0x30000000000E4081);
        QUAD(0x30000000000E5081);
        QUAD(0x30000000000E6081);
        QUAD(0x30000000000E7081);
        QUAD(0x30000000000E8081);
        QUAD(0x30000000000E9081);
        QUAD(0x30000000000EA081);
        QUAD(0x30000000000EB081);
        QUAD(0x30000000000EC081);
        QUAD(0x30000000000ED081);
        QUAD(0x30000000000EE081);
        QUAD(0x30000000000EF081);
        QUAD(0x30000000000F0081);
        QUAD(0x30000000000F1081);
        QUAD(0x30000000000F2081);
        QUAD(0x30000000000F3081);
        QUAD(0x30000000000F4081);
        QUAD(0x30000000000F5081);
        QUAD(0x30000000000F6081);
        QUAD(0x30000000000F7081);
        QUAD(0x30000000000F8081);
        QUAD(0x30000000000F9081);
        QUAD(0x30000000000FA081);
        QUAD(0x30000000000FB081);
        QUAD(0x30000000000FC081);
        QUAD(0x30000000000FD081);
        QUAD(0x30000000000FE081);
        QUAD(0x30000000000FF081);
        QUAD(0x3000000000100081);
        QUAD(0x3000000000101081);
        QUAD(0x3000000000102081);
        QUAD(0x3000000000103081);
        QUAD(0x3000000000104081);
        QUAD(0x3000000000105081);
        QUAD(0x3000000000106081);
        QUAD(0x3000000000107081);
        QUAD(0x3000000000108081);
        QUAD(0x3000000000109081);
        QUAD(0x300000000010A081);
        QUAD(0x300000000010B081);
        QUAD(0x300000000010C081);
        QUAD(0x300000000010D081);
        QUAD(0x300000000010E081);
        QUAD(0x300000000010F081);
        QUAD(0x3000000000110081);
        QUAD(0x3000000000111081);
        QUAD(0x3000000000112081);
        QUAD(0x3000000000113081);
        QUAD(0x3000000000114081);
        QUAD(0x3000000000115081);
        QUAD(0x3000000000116081);
        QUAD(0x3000000000117081);
        QUAD(0x3000000000118081);
        QUAD(0x3000000000119081);
        QUAD(0x300000000011A081);
        QUAD(0x300000000011B081);
        QUAD(0x300000000011C081);
        QUAD(0x300000000011D081);
        QUAD(0x300000000011E081);
        QUAD(0x300000000011F081);
        QUAD(0x3000000000120081);
        QUAD(0x3000000000121081);
        QUAD(0x3000000000122081);
        QUAD(0x3000000000123081);
        QUAD(0x3000000000124081);
        QUAD(0x3000000000125081);
        QUAD(0x3000000000126081);
        QUAD(0x3000000000127081);
        QUAD(0x3000000000128081);
        QUAD(0x3000000000129081);
        QUAD(0x300000000012A081);
        QUAD(0x300000000012B081);
        QUAD(0x300000000012C081);
        QUAD(0x300000000012D081);
        QUAD(0x300000000012E081);
        QUAD(0x300000000012F081);
        QUAD(0x3000000000130081);
        QUAD(0x3000000000131081);
        QUAD(0x3000000000132081);
        QUAD(0x3000000000133081);
        QUAD(0x3000000000134081);
        QUAD(0x3000000000135081);
        QUAD(0x3000000000136081);
        QUAD(0x3000000000137081);
        QUAD(0x3000000000138081);
        QUAD(0x3000000000139081);
        QUAD(0x300000000013A081);
        QUAD(0x300000000013B081);
        QUAD(0x300000000013C081);
        QUAD(0x300000000013D081);
        QUAD(0x300000000013E081);
        QUAD(0x300000000013F081);
        QUAD(0x3000000000140081);
        QUAD(0x3000000000141081);
        QUAD(0x3000000000142081);
        QUAD(0x3000000000143081);
        QUAD(0x3000000000144081);
        QUAD(0x3000000000145081);
        QUAD(0x3000000000146081);
        QUAD(0x3000000000147081);
        QUAD(0x3000000000148081);
        QUAD(0x3000000000149081);
        QUAD(0x300000000014A081);
        QUAD(0x300000000014B081);
        QUAD(0x300000000014C081);
        QUAD(0x300000000014D081);
        QUAD(0x300000000014E081);
        QUAD(0x300000000014F081);
        QUAD(0x3000000000150081);
        QUAD(0x3000000000151081);
        QUAD(0x3000000000152081);
        QUAD(0x3000000000153081);
        QUAD(0x3000000000154081);
        QUAD(0x3000000000155081);
        QUAD(0x3000000000156081);
        QUAD(0x3000000000157081);
        QUAD(0x3000000000158081);
        QUAD(0x3000000000159081);
        QUAD(0x300000000015A081);
        QUAD(0x300000000015B081);
        QUAD(0x300000000015C081);
        QUAD(0x300000000015D081);
        QUAD(0x300000000015E081);
        QUAD(0x300000000015F081);
        QUAD(0x3000000000160081);
        QUAD(0x3000000000161081);
        QUAD(0x3000000000162081);
        QUAD(0x3000000000163081);
        QUAD(0x3000000000164081);
        QUAD(0x3000000000165081);
        QUAD(0x3000000000166081);
        QUAD(0x3000000000167081);
        QUAD(0x3000000000168081);
        QUAD(0x3000000000169081);
        QUAD(0x300000000016A081);
        QUAD(0x300000000016B081);
        QUAD(0x300000000016C081);
        QUAD(0x300000000016D081);
        QUAD(0x300000000016E081);
        QUAD(0x300000000016F081);
        QUAD(0x3000000000170081);
        QUAD(0x3000000000171081);
        QUAD(0x3000000000172081);
        QUAD(0x3000000000173081);
        QUAD(0x3000000000174081);
        QUAD(0x3000000000175081);
        QUAD(0x3000000000176081);
        QUAD(0x3000000000177081);
        QUAD(0x3000000000178081);
        QUAD(0x3000000000179081);
        QUAD(0x300000000017A081);
        QUAD(0x300000000017B081);
        QUAD(0x300000000017C081);
        QUAD(0x300000000017D081);
        QUAD(0x300000000017E081);
        QUAD(0x300000000017F081);
        QUAD(0x3000000000180081);
        QUAD(0x3000000000181081);
        QUAD(0x3000000000182081);
        QUAD(0x3000000000183081);
        QUAD(0x3000000000184081);
        QUAD(0x3000000000185081);
        QUAD(0x3000000000186081);
        QUAD(0x3000000000187081);
        QUAD(0x3000000000188081);
        QUAD(0x3000000000189081);
        QUAD(0x300000000018A081);
        QUAD(0x300000000018B081);
        QUAD(0x300000000018C081);
        QUAD(0x300000000018D081);
        QUAD(0x300000000018E081);
        QUAD(0x300000000018F081);
        QUAD(0x3000000000190081);
        QUAD(0x3000000000191081);
        QUAD(0x3000000000192081);
        QUAD(0x3000000000193081);
        QUAD(0x3000000000194081);
        QUAD(0x3000000000195081);
        QUAD(0x3000000000196081);
        QUAD(0x3000000000197081);
        QUAD(0x3000000000198081);
        QUAD(0x3000000000199081);
        QUAD(0x300000000019A081);
        QUAD(0x300000000019B081);
        QUAD(0x300000000019C081);
        QUAD(0x300000000019D081);
        QUAD(0x300000000019E081);
        QUAD(0x300000000019F081);
        QUAD(0x30000000001A0081);
        QUAD(0x30000000001A1081);
        QUAD(0x30000000001A2081);
        QUAD(0x30000000001A3081);
        QUAD(0x30000000001A4081);
        QUAD(0x30000000001A5081);
        QUAD(0x30000000001A6081);
        QUAD(0x30000000001A7081);
        QUAD(0x30000000001A8081);
        QUAD(0x30000000001A9081);
        QUAD(0x30000000001AA081);
        QUAD(0x30000000001AB081);
        QUAD(0x30000000001AC081);
        QUAD(0x30000000001AD081);
        QUAD(0x30000000001AE081);
        QUAD(0x30000000001AF081);
        QUAD(0x30000000001B0081);
        QUAD(0x30000000001B1081);
        QUAD(0x30000000001B2081);
        QUAD(0x30000000001B3081);
        QUAD(0x30000000001B4081);
        QUAD(0x30000000001B5081);
        QUAD(0x30000000001B6081);
        QUAD(0x30000000001B7081);
        QUAD(0x30000000001B8081);
        QUAD(0x30000000001B9081);
        QUAD(0x30000000001BA081);
        QUAD(0x30000000001BB081);
        QUAD(0x30000000001BC081);
        QUAD(0x30000000001BD081);
        QUAD(0x30000000001BE081);
        QUAD(0x30000000001BF081);
        QUAD(0x30000000001C0081);
        QUAD(0x30000000001C1081);
        QUAD(0x30000000001C2081);
        QUAD(0x30000000001C3081);
        QUAD(0x30000000001C4081);
        QUAD(0x30000000001C5081);
        QUAD(0x30000000001C6081);
        QUAD(0x30000000001C7081);
        QUAD(0x30000000001C8081);
        QUAD(0x30000000001C9081);
        QUAD(0x30000000001CA081);
        QUAD(0x30000000001CB081);
        QUAD(0x30000000001CC081);
        QUAD(0x30000000001CD081);
        QUAD(0x30000000001CE081);
        QUAD(0x30000000001CF081);
        QUAD(0x30000000001D0081);
        QUAD(0x30000000001D1081);
        QUAD(0x30000000001D2081);
        QUAD(0x30000000001D3081);
        QUAD(0x30000000001D4081);
        QUAD(0x30000000001D5081);
        QUAD(0x30000000001D6081);
        QUAD(0x30000000001D7081);
        QUAD(0x30000000001D8081);
        QUAD(0x30000000001D9081);
        QUAD(0x30000000001DA081);
        QUAD(0x30000000001DB081);
        QUAD(0x30000000001DC081);
        QUAD(0x30000000001DD081);
        QUAD(0x30000000001DE081);
        QUAD(0x30000000001DF081);
        QUAD(0x30000000001E0081);
        QUAD(0x30000000001E1081);
        QUAD(0x30000000001E2081);
        QUAD(0x30000000001E3081);
        QUAD(0x30000000001E4081);
        QUAD(0x30000000001E5081);
        QUAD(0x30000000001E6081);
        QUAD(0x30000000001E7081);
        QUAD(0x30000000001E8081);
        QUAD(0x30000000001E9081);
        QUAD(0x30000000001EA081);
        QUAD(0x30000000001EB081);
        QUAD(0x30000000001EC081);
        QUAD(0x30000000001ED081);
        QUAD(0x30000000001EE081);
        QUAD(0x30000000001EF081);
        QUAD(0x30000000001F0081);   /* Guard page */
        QUAD(0xB0000000001F1083);   /* Kernel stack */
        QUAD(0xB0000000001F2083);   /* Kernel stack */
        QUAD(0xB0000000001F3083);   /* Kernel stack */
        QUAD(0xB0000000001F4083);   /* Kernel stack */
        QUAD(0xB0000000001F5083);   /* Kernel stack */
        QUAD(0xB0000000001F6083);   /* Kernel stack */
        QUAD(0xB0000000001F7083);   /* Kernel stack */
        QUAD(0xB0000000001F8083);   /* Kernel stack */
        QUAD(0xB0000000001F9083);   /* Kernel stack */
        QUAD(0xB0000000001FA083);   /* Kernel stack */
        QUAD(0xB0000000001FB083);   /* Kernel stack */
        QUAD(0xB0000000001FC083);   /* Kernel stack */
        QUAD(0xB0000000001FD083);   /* Kernel stack */
        QUAD(0xB0000000001FE083);   /* Kernel stack */
        QUAD(0x30000000001FF081);   /* Guard page - read only, holds kargs */

        /* _page_table + 0x4000 */
        . = ALIGN(4096);
        QUAD(0);                                          /*0xFFFFFF8000000000*/
        QUAD(0);                                          /*0xFFFFFF8040000000*/
        QUAD(0);                                          /*0xFFFFFF8080000000*/
        QUAD(0);                                          /*0xFFFFFF80C0000000*/
        QUAD(0);                                          /*0xFFFFFF8100000000*/
        QUAD(0);                                          /*0xFFFFFF8140000000*/
        QUAD(0);                                          /*0xFFFFFF8180000000*/
        QUAD(0);                                          /*0xFFFFFF81C0000000*/
        QUAD(0);                                          /*0xFFFFFF8200000000*/
        QUAD(0);                                          /*0xFFFFFF8240000000*/
        QUAD(0);                                          /*0xFFFFFF8280000000*/
        QUAD(0);                                          /*0xFFFFFF82C0000000*/
        QUAD(0);                                          /*0xFFFFFF8300000000*/
        QUAD(0);                                          /*0xFFFFFF8340000000*/
        QUAD(0);                                          /*0xFFFFFF8380000000*/
        QUAD(0);                                          /*0xFFFFFF83C0000000*/
        QUAD(0);                                          /*0xFFFFFF8400000000*/
        QUAD(0);                                          /*0xFFFFFF8440000000*/
        QUAD(0);                                          /*0xFFFFFF8480000000*/
        QUAD(0);                                          /*0xFFFFFF84C0000000*/
        QUAD(0);                                          /*0xFFFFFF8500000000*/
        QUAD(0);                                          /*0xFFFFFF8540000000*/
        QUAD(0);                                          /*0xFFFFFF8580000000*/
        QUAD(0);                                          /*0xFFFFFF85C0000000*/
        QUAD(0);                                          /*0xFFFFFF8600000000*/
        QUAD(0);                                          /*0xFFFFFF8640000000*/
        QUAD(0);                                          /*0xFFFFFF8680000000*/
        QUAD(0);                                          /*0xFFFFFF86C0000000*/
        QUAD(0);                                          /*0xFFFFFF8700000000*/
        QUAD(0);                                          /*0xFFFFFF8740000000*/
        QUAD(0);                                          /*0xFFFFFF8780000000*/
        QUAD(0);                                          /*0xFFFFFF87C0000000*/
        QUAD(0);                                          /*0xFFFFFF8800000000*/
        QUAD(0);                                          /*0xFFFFFF8840000000*/
        QUAD(0);                                          /*0xFFFFFF8880000000*/
        QUAD(0);                                          /*0xFFFFFF88C0000000*/
        QUAD(0);                                          /*0xFFFFFF8900000000*/
        QUAD(0);                                          /*0xFFFFFF8940000000*/
        QUAD(0);                                          /*0xFFFFFF8980000000*/
        QUAD(0);                                          /*0xFFFFFF89C0000000*/
        QUAD(0);                                          /*0xFFFFFF8A00000000*/
        QUAD(0);                                          /*0xFFFFFF8A40000000*/
        QUAD(0);                                          /*0xFFFFFF8A80000000*/
        QUAD(0);                                          /*0xFFFFFF8AC0000000*/
        QUAD(0);                                          /*0xFFFFFF8B00000000*/
        QUAD(0);                                          /*0xFFFFFF8B40000000*/
        QUAD(0);                                          /*0xFFFFFF8B80000000*/
        QUAD(0);                                          /*0xFFFFFF8BC0000000*/
        QUAD(0);                                          /*0xFFFFFF8C00000000*/
        QUAD(0);                                          /*0xFFFFFF8C40000000*/
        QUAD(0);                                          /*0xFFFFFF8C80000000*/
        QUAD(0);                                          /*0xFFFFFF8CC0000000*/
        QUAD(0);                                          /*0xFFFFFF8D00000000*/
        QUAD(0);                                          /*0xFFFFFF8D40000000*/
        QUAD(0);                                          /*0xFFFFFF8D80000000*/
        QUAD(0);                                          /*0xFFFFFF8DC0000000*/
        QUAD(0);                                          /*0xFFFFFF8E00000000*/
        QUAD(0);                                          /*0xFFFFFF8E40000000*/
        QUAD(0);                                          /*0xFFFFFF8E80000000*/
        QUAD(0);                                          /*0xFFFFFF8EC0000000*/
        QUAD(0);                                          /*0xFFFFFF8F00000000*/
        QUAD(0);                                          /*0xFFFFFF8F40000000*/
        QUAD(0);                                          /*0xFFFFFF8F80000000*/
        QUAD(0);                                          /*0xFFFFFF8FC0000000*/
        QUAD(0);                                          /*0xFFFFFF9000000000*/
        QUAD(0);                                          /*0xFFFFFF9040000000*/
        QUAD(0);                                          /*0xFFFFFF9080000000*/
        QUAD(0);                                          /*0xFFFFFF90C0000000*/
        QUAD(0);                                          /*0xFFFFFF9100000000*/
        QUAD(0);                                          /*0xFFFFFF9140000000*/
        QUAD(0);                                          /*0xFFFFFF9180000000*/
        QUAD(0);                                          /*0xFFFFFF91C0000000*/
        QUAD(0);                                          /*0xFFFFFF9200000000*/
        QUAD(0);                                          /*0xFFFFFF9240000000*/
        QUAD(0);                                          /*0xFFFFFF9280000000*/
        QUAD(0);                                          /*0xFFFFFF92C0000000*/
        QUAD(0);                                          /*0xFFFFFF9300000000*/
        QUAD(0);                                          /*0xFFFFFF9340000000*/
        QUAD(0);                                          /*0xFFFFFF9380000000*/
        QUAD(0);                                          /*0xFFFFFF93C0000000*/
        QUAD(0);                                          /*0xFFFFFF9400000000*/
        QUAD(0);                                          /*0xFFFFFF9440000000*/
        QUAD(0);                                          /*0xFFFFFF9480000000*/
        QUAD(0);                                          /*0xFFFFFF94C0000000*/
        QUAD(0);                                          /*0xFFFFFF9500000000*/
        QUAD(0);                                          /*0xFFFFFF9540000000*/
        QUAD(0);                                          /*0xFFFFFF9580000000*/
        QUAD(0);                                          /*0xFFFFFF95C0000000*/
        QUAD(0);                                          /*0xFFFFFF9600000000*/
        QUAD(0);                                          /*0xFFFFFF9640000000*/
        QUAD(0);                                          /*0xFFFFFF9680000000*/
        QUAD(0);                                          /*0xFFFFFF96C0000000*/
        QUAD(0);                                          /*0xFFFFFF9700000000*/
        QUAD(0);                                          /*0xFFFFFF9740000000*/
        QUAD(0);                                          /*0xFFFFFF9780000000*/
        QUAD(0);                                          /*0xFFFFFF97C0000000*/
        QUAD(0);                                          /*0xFFFFFF9800000000*/
        QUAD(0);                                          /*0xFFFFFF9840000000*/
        QUAD(0);                                          /*0xFFFFFF9880000000*/
        QUAD(0);                                          /*0xFFFFFF98C0000000*/
        QUAD(0);                                          /*0xFFFFFF9900000000*/
        QUAD(0);                                          /*0xFFFFFF9940000000*/
        QUAD(0);                                          /*0xFFFFFF9980000000*/
        QUAD(0);                                          /*0xFFFFFF99C0000000*/
        QUAD(0);                                          /*0xFFFFFF9A00000000*/
        QUAD(0);                                          /*0xFFFFFF9A40000000*/
        QUAD(0);                                          /*0xFFFFFF9A80000000*/
        QUAD(0);                                          /*0xFFFFFF9AC0000000*/
        QUAD(0);                                          /*0xFFFFFF9B00000000*/
        QUAD(0);                                          /*0xFFFFFF9B40000000*/
        QUAD(0);                                          /*0xFFFFFF9B80000000*/
        QUAD(0);                                          /*0xFFFFFF9BC0000000*/
        QUAD(0);                                          /*0xFFFFFF9C00000000*/
        QUAD(0);                                          /*0xFFFFFF9C40000000*/
        QUAD(0);                                          /*0xFFFFFF9C80000000*/
        QUAD(0);                                          /*0xFFFFFF9CC0000000*/
        QUAD(0);                                          /*0xFFFFFF9D00000000*/
        QUAD(0);                                          /*0xFFFFFF9D40000000*/
        QUAD(0);                                          /*0xFFFFFF9D80000000*/
        QUAD(0);                                          /*0xFFFFFF9DC0000000*/
        QUAD(0);                                          /*0xFFFFFF9E00000000*/
        QUAD(0);                                          /*0xFFFFFF9E40000000*/
        QUAD(0);                                          /*0xFFFFFF9E80000000*/
        QUAD(0);                                          /*0xFFFFFF9EC0000000*/
        QUAD(0);                                          /*0xFFFFFF9F00000000*/
        QUAD(0);                                          /*0xFFFFFF9F40000000*/
        QUAD(0);                                          /*0xFFFFFF9F80000000*/
        QUAD(0);                                          /*0xFFFFFF9FC0000000*/
        QUAD(0);                                          /*0xFFFFFFA000000000*/
        QUAD(0);                                          /*0xFFFFFFA040000000*/
        QUAD(0);                                          /*0xFFFFFFA080000000*/
        QUAD(0);                                          /*0xFFFFFFA0C0000000*/
        QUAD(0);                                          /*0xFFFFFFA100000000*/
        QUAD(0);                                          /*0xFFFFFFA140000000*/
        QUAD(0);                                          /*0xFFFFFFA180000000*/
        QUAD(0);                                          /*0xFFFFFFA1C0000000*/
        QUAD(0);                                          /*0xFFFFFFA200000000*/
        QUAD(0);                                          /*0xFFFFFFA240000000*/
        QUAD(0);                                          /*0xFFFFFFA280000000*/
        QUAD(0);                                          /*0xFFFFFFA2C0000000*/
        QUAD(0);                                          /*0xFFFFFFA300000000*/
        QUAD(0);                                          /*0xFFFFFFA340000000*/
        QUAD(0);                                          /*0xFFFFFFA380000000*/
        QUAD(0);                                          /*0xFFFFFFA3C0000000*/
        QUAD(0);                                          /*0xFFFFFFA400000000*/
        QUAD(0);                                          /*0xFFFFFFA440000000*/
        QUAD(0);                                          /*0xFFFFFFA480000000*/
        QUAD(0);                                          /*0xFFFFFFA4C0000000*/
        QUAD(0);                                          /*0xFFFFFFA500000000*/
        QUAD(0);                                          /*0xFFFFFFA540000000*/
        QUAD(0);                                          /*0xFFFFFFA580000000*/
        QUAD(0);                                          /*0xFFFFFFA5C0000000*/
        QUAD(0);                                          /*0xFFFFFFA600000000*/
        QUAD(0);                                          /*0xFFFFFFA640000000*/
        QUAD(0);                                          /*0xFFFFFFA680000000*/
        QUAD(0);                                          /*0xFFFFFFA6C0000000*/
        QUAD(0);                                          /*0xFFFFFFA700000000*/
        QUAD(0);                                          /*0xFFFFFFA740000000*/
        QUAD(0);                                          /*0xFFFFFFA780000000*/
        QUAD(0);                                          /*0xFFFFFFA7C0000000*/
        QUAD(0);                                          /*0xFFFFFFA800000000*/
        QUAD(0);                                          /*0xFFFFFFA840000000*/
        QUAD(0);                                          /*0xFFFFFFA880000000*/
        QUAD(0);                                          /*0xFFFFFFA8C0000000*/
        QUAD(0);                                          /*0xFFFFFFA900000000*/
        QUAD(0);                                          /*0xFFFFFFA940000000*/
        QUAD(0);                                          /*0xFFFFFFA980000000*/
        QUAD(0);                                          /*0xFFFFFFA9C0000000*/
        QUAD(0);                                          /*0xFFFFFFAA00000000*/
        QUAD(0);                                          /*0xFFFFFFAA40000000*/
        QUAD(0);                                          /*0xFFFFFFAA80000000*/
        QUAD(0);                                          /*0xFFFFFFAAC0000000*/
        QUAD(0);                                          /*0xFFFFFFAB00000000*/
        QUAD(0);                                          /*0xFFFFFFAB40000000*/
        QUAD(0);                                          /*0xFFFFFFAB80000000*/
        QUAD(0);                                          /*0xFFFFFFABC0000000*/
        QUAD(0);                                          /*0xFFFFFFAC00000000*/
        QUAD(0);                                          /*0xFFFFFFAC40000000*/
        QUAD(0);                                          /*0xFFFFFFAC80000000*/
        QUAD(0);                                          /*0xFFFFFFACC0000000*/
        QUAD(0);                                          /*0xFFFFFFAD00000000*/
        QUAD(0);                                          /*0xFFFFFFAD40000000*/
        QUAD(0);                                          /*0xFFFFFFAD80000000*/
        QUAD(0);                                          /*0xFFFFFFADC0000000*/
        QUAD(0);                                          /*0xFFFFFFAE00000000*/
        QUAD(0);                                          /*0xFFFFFFAE40000000*/
        QUAD(0);                                          /*0xFFFFFFAE80000000*/
        QUAD(0);                                          /*0xFFFFFFAEC0000000*/
        QUAD(0);                                          /*0xFFFFFFAF00000000*/
        QUAD(0);                                          /*0xFFFFFFAF40000000*/
        QUAD(0);                                          /*0xFFFFFFAF80000000*/
        QUAD(0);                                          /*0xFFFFFFAFC0000000*/
        QUAD(0);                                          /*0xFFFFFFB000000000*/
        QUAD(0);                                          /*0xFFFFFFB040000000*/
        QUAD(0);                                          /*0xFFFFFFB080000000*/
        QUAD(0);                                          /*0xFFFFFFB0C0000000*/
        QUAD(0);                                          /*0xFFFFFFB100000000*/
        QUAD(0);                                          /*0xFFFFFFB140000000*/
        QUAD(0);                                          /*0xFFFFFFB180000000*/
        QUAD(0);                                          /*0xFFFFFFB1C0000000*/
        QUAD(0);                                          /*0xFFFFFFB200000000*/
        QUAD(0);                                          /*0xFFFFFFB240000000*/
        QUAD(0);                                          /*0xFFFFFFB280000000*/
        QUAD(0);                                          /*0xFFFFFFB2C0000000*/
        QUAD(0);                                          /*0xFFFFFFB300000000*/
        QUAD(0);                                          /*0xFFFFFFB340000000*/
        QUAD(0);                                          /*0xFFFFFFB380000000*/
        QUAD(0);                                          /*0xFFFFFFB3C0000000*/
        QUAD(0);                                          /*0xFFFFFFB400000000*/
        QUAD(0);                                          /*0xFFFFFFB440000000*/
        QUAD(0);                                          /*0xFFFFFFB480000000*/
        QUAD(0);                                          /*0xFFFFFFB4C0000000*/
        QUAD(0);                                          /*0xFFFFFFB500000000*/
        QUAD(0);                                          /*0xFFFFFFB540000000*/
        QUAD(0);                                          /*0xFFFFFFB580000000*/
        QUAD(0);                                          /*0xFFFFFFB5C0000000*/
        QUAD(0);                                          /*0xFFFFFFB600000000*/
        QUAD(0);                                          /*0xFFFFFFB640000000*/
        QUAD(0);                                          /*0xFFFFFFB680000000*/
        QUAD(0);                                          /*0xFFFFFFB6C0000000*/
        QUAD(0);                                          /*0xFFFFFFB700000000*/
        QUAD(0);                                          /*0xFFFFFFB740000000*/
        QUAD(0);                                          /*0xFFFFFFB780000000*/
        QUAD(0);                                          /*0xFFFFFFB7C0000000*/
        QUAD(0);                                          /*0xFFFFFFB800000000*/
        QUAD(0);                                          /*0xFFFFFFB840000000*/
        QUAD(0);                                          /*0xFFFFFFB880000000*/
        QUAD(0);                                          /*0xFFFFFFB8C0000000*/
        QUAD(0);                                          /*0xFFFFFFB900000000*/
        QUAD(0);                                          /*0xFFFFFFB940000000*/
        QUAD(0);                                          /*0xFFFFFFB980000000*/
        QUAD(0);                                          /*0xFFFFFFB9C0000000*/
        QUAD(0);                                          /*0xFFFFFFBA00000000*/
        QUAD(0);                                          /*0xFFFFFFBA40000000*/
        QUAD(0);                                          /*0xFFFFFFBA80000000*/
        QUAD(0);                                          /*0xFFFFFFBAC0000000*/
        QUAD(0);                                          /*0xFFFFFFBB00000000*/
        QUAD(0);                                          /*0xFFFFFFBB40000000*/
        QUAD(0);                                          /*0xFFFFFFBB80000000*/
        QUAD(0);                                          /*0xFFFFFFBBC0000000*/
        QUAD(0);                                          /*0xFFFFFFBC00000000*/
        QUAD(0);                                          /*0xFFFFFFBC40000000*/
        QUAD(0);                                          /*0xFFFFFFBC80000000*/
        QUAD(0);                                          /*0xFFFFFFBCC0000000*/
        QUAD(0);                                          /*0xFFFFFFBD00000000*/
        QUAD(0);                                          /*0xFFFFFFBD40000000*/
        QUAD(0);                                          /*0xFFFFFFBD80000000*/
        QUAD(0);                                          /*0xFFFFFFBDC0000000*/
        QUAD(0);                                          /*0xFFFFFFBE00000000*/
        QUAD(0);                                          /*0xFFFFFFBE40000000*/
        QUAD(0);                                          /*0xFFFFFFBE80000000*/
        QUAD(0);                                          /*0xFFFFFFBEC0000000*/
        QUAD(0);                                          /*0xFFFFFFBF00000000*/
        QUAD(0);                                          /*0xFFFFFFBF40000000*/
        QUAD(0);                                          /*0xFFFFFFBF80000000*/
        QUAD(0);                                          /*0xFFFFFFBFC0000000*/
        QUAD(0);                                          /*0xFFFFFFC000000000*/
        QUAD(0);                                          /*0xFFFFFFC040000000*/
        QUAD(0);                                          /*0xFFFFFFC080000000*/
        QUAD(0);                                          /*0xFFFFFFC0C0000000*/
        QUAD(0);                                          /*0xFFFFFFC100000000*/
        QUAD(0);                                          /*0xFFFFFFC140000000*/
        QUAD(0);                                          /*0xFFFFFFC180000000*/
        QUAD(0);                                          /*0xFFFFFFC1C0000000*/
        QUAD(0);                                          /*0xFFFFFFC200000000*/
        QUAD(0);                                          /*0xFFFFFFC240000000*/
        QUAD(0);                                          /*0xFFFFFFC280000000*/
        QUAD(0);                                          /*0xFFFFFFC2C0000000*/
        QUAD(0);                                          /*0xFFFFFFC300000000*/
        QUAD(0);                                          /*0xFFFFFFC340000000*/
        QUAD(0);                                          /*0xFFFFFFC380000000*/
        QUAD(0);                                          /*0xFFFFFFC3C0000000*/
        QUAD(0);                                          /*0xFFFFFFC400000000*/
        QUAD(0);                                          /*0xFFFFFFC440000000*/
        QUAD(0);                                          /*0xFFFFFFC480000000*/
        QUAD(0);                                          /*0xFFFFFFC4C0000000*/
        QUAD(0);                                          /*0xFFFFFFC500000000*/
        QUAD(0);                                          /*0xFFFFFFC540000000*/
        QUAD(0);                                          /*0xFFFFFFC580000000*/
        QUAD(0);                                          /*0xFFFFFFC5C0000000*/
        QUAD(0);                                          /*0xFFFFFFC600000000*/
        QUAD(0);                                          /*0xFFFFFFC640000000*/
        QUAD(0);                                          /*0xFFFFFFC680000000*/
        QUAD(0);                                          /*0xFFFFFFC6C0000000*/
        QUAD(0);                                          /*0xFFFFFFC700000000*/
        QUAD(0);                                          /*0xFFFFFFC740000000*/
        QUAD(0);                                          /*0xFFFFFFC780000000*/
        QUAD(0);                                          /*0xFFFFFFC7C0000000*/
        QUAD(0);                                          /*0xFFFFFFC800000000*/
        QUAD(0);                                          /*0xFFFFFFC840000000*/
        QUAD(0);                                          /*0xFFFFFFC880000000*/
        QUAD(0);                                          /*0xFFFFFFC8C0000000*/
        QUAD(0);                                          /*0xFFFFFFC900000000*/
        QUAD(0);                                          /*0xFFFFFFC940000000*/
        QUAD(0);                                          /*0xFFFFFFC980000000*/
        QUAD(0);                                          /*0xFFFFFFC9C0000000*/
        QUAD(0);                                          /*0xFFFFFFCA00000000*/
        QUAD(0);                                          /*0xFFFFFFCA40000000*/
        QUAD(0);                                          /*0xFFFFFFCA80000000*/
        QUAD(0);                                          /*0xFFFFFFCAC0000000*/
        QUAD(0);                                          /*0xFFFFFFCB00000000*/
        QUAD(0);                                          /*0xFFFFFFCB40000000*/
        QUAD(0);                                          /*0xFFFFFFCB80000000*/
        QUAD(0);                                          /*0xFFFFFFCBC0000000*/
        QUAD(0);                                          /*0xFFFFFFCC00000000*/
        QUAD(0);                                          /*0xFFFFFFCC40000000*/
        QUAD(0);                                          /*0xFFFFFFCC80000000*/
        QUAD(0);                                          /*0xFFFFFFCCC0000000*/
        QUAD(0);                                          /*0xFFFFFFCD00000000*/
        QUAD(0);                                          /*0xFFFFFFCD40000000*/
        QUAD(0);                                          /*0xFFFFFFCD80000000*/
        QUAD(0);                                          /*0xFFFFFFCDC0000000*/
        QUAD(0);                                          /*0xFFFFFFCE00000000*/
        QUAD(0);                                          /*0xFFFFFFCE40000000*/
        QUAD(0);                                          /*0xFFFFFFCE80000000*/
        QUAD(0);                                          /*0xFFFFFFCEC0000000*/
        QUAD(0);                                          /*0xFFFFFFCF00000000*/
        QUAD(0);                                          /*0xFFFFFFCF40000000*/
        QUAD(0);                                          /*0xFFFFFFCF80000000*/
        QUAD(0);                                          /*0xFFFFFFCFC0000000*/
        QUAD(0);                                          /*0xFFFFFFD000000000*/
        QUAD(0);                                          /*0xFFFFFFD040000000*/
        QUAD(0);                                          /*0xFFFFFFD080000000*/
        QUAD(0);                                          /*0xFFFFFFD0C0000000*/
        QUAD(0);                                          /*0xFFFFFFD100000000*/
        QUAD(0);                                          /*0xFFFFFFD140000000*/
        QUAD(0);                                          /*0xFFFFFFD180000000*/
        QUAD(0);                                          /*0xFFFFFFD1C0000000*/
        QUAD(0);                                          /*0xFFFFFFD200000000*/
        QUAD(0);                                          /*0xFFFFFFD240000000*/
        QUAD(0);                                          /*0xFFFFFFD280000000*/
        QUAD(0);                                          /*0xFFFFFFD2C0000000*/
        QUAD(0);                                          /*0xFFFFFFD300000000*/
        QUAD(0);                                          /*0xFFFFFFD340000000*/
        QUAD(0);                                          /*0xFFFFFFD380000000*/
        QUAD(0);                                          /*0xFFFFFFD3C0000000*/
        QUAD(0);                                          /*0xFFFFFFD400000000*/
        QUAD(0);                                          /*0xFFFFFFD440000000*/
        QUAD(0);                                          /*0xFFFFFFD480000000*/
        QUAD(0);                                          /*0xFFFFFFD4C0000000*/
        QUAD(0);                                          /*0xFFFFFFD500000000*/
        QUAD(0);                                          /*0xFFFFFFD540000000*/
        QUAD(0);                                          /*0xFFFFFFD580000000*/
        QUAD(0);                                          /*0xFFFFFFD5C0000000*/
        QUAD(0);                                          /*0xFFFFFFD600000000*/
        QUAD(0);                                          /*0xFFFFFFD640000000*/
        QUAD(0);                                          /*0xFFFFFFD680000000*/
        QUAD(0);                                          /*0xFFFFFFD6C0000000*/
        QUAD(0);                                          /*0xFFFFFFD700000000*/
        QUAD(0);                                          /*0xFFFFFFD740000000*/
        QUAD(0);                                          /*0xFFFFFFD780000000*/
        QUAD(0);                                          /*0xFFFFFFD7C0000000*/
        QUAD(0);                                          /*0xFFFFFFD800000000*/
        QUAD(0);                                          /*0xFFFFFFD840000000*/
        QUAD(0);                                          /*0xFFFFFFD880000000*/
        QUAD(0);                                          /*0xFFFFFFD8C0000000*/
        QUAD(0);                                          /*0xFFFFFFD900000000*/
        QUAD(0);                                          /*0xFFFFFFD940000000*/
        QUAD(0);                                          /*0xFFFFFFD980000000*/
        QUAD(0);                                          /*0xFFFFFFD9C0000000*/
        QUAD(0);                                          /*0xFFFFFFDA00000000*/
        QUAD(0);                                          /*0xFFFFFFDA40000000*/
        QUAD(0);                                          /*0xFFFFFFDA80000000*/
        QUAD(0);                                          /*0xFFFFFFDAC0000000*/
        QUAD(0);                                          /*0xFFFFFFDB00000000*/
        QUAD(0);                                          /*0xFFFFFFDB40000000*/
        QUAD(0);                                          /*0xFFFFFFDB80000000*/
        QUAD(0);                                          /*0xFFFFFFDBC0000000*/
        QUAD(0);                                          /*0xFFFFFFDC00000000*/
        QUAD(0);                                          /*0xFFFFFFDC40000000*/
        QUAD(0);                                          /*0xFFFFFFDC80000000*/
        QUAD(0);                                          /*0xFFFFFFDCC0000000*/
        QUAD(0);                                          /*0xFFFFFFDD00000000*/
        QUAD(0);                                          /*0xFFFFFFDD40000000*/
        QUAD(0);                                          /*0xFFFFFFDD80000000*/
        QUAD(0);                                          /*0xFFFFFFDDC0000000*/
        QUAD(0);                                          /*0xFFFFFFDE00000000*/
        QUAD(0);                                          /*0xFFFFFFDE40000000*/
        QUAD(0);                                          /*0xFFFFFFDE80000000*/
        QUAD(0);                                          /*0xFFFFFFDEC0000000*/
        QUAD(0);                                          /*0xFFFFFFDF00000000*/
        QUAD(0);                                          /*0xFFFFFFDF40000000*/
        QUAD(0);                                          /*0xFFFFFFDF80000000*/
        QUAD(0);                                          /*0xFFFFFFDFC0000000*/
        QUAD(0);                                          /*0xFFFFFFE000000000*/
        QUAD(0);                                          /*0xFFFFFFE040000000*/
        QUAD(0);                                          /*0xFFFFFFE080000000*/
        QUAD(0);                                          /*0xFFFFFFE0C0000000*/
        QUAD(0);                                          /*0xFFFFFFE100000000*/
        QUAD(0);                                          /*0xFFFFFFE140000000*/
        QUAD(0);                                          /*0xFFFFFFE180000000*/
        QUAD(0);                                          /*0xFFFFFFE1C0000000*/
        QUAD(0);                                          /*0xFFFFFFE200000000*/
        QUAD(0);                                          /*0xFFFFFFE240000000*/
        QUAD(0);                                          /*0xFFFFFFE280000000*/
        QUAD(0);                                          /*0xFFFFFFE2C0000000*/
        QUAD(0);                                          /*0xFFFFFFE300000000*/
        QUAD(0);                                          /*0xFFFFFFE340000000*/
        QUAD(0);                                          /*0xFFFFFFE380000000*/
        QUAD(0);                                          /*0xFFFFFFE3C0000000*/
        QUAD(0);                                          /*0xFFFFFFE400000000*/
        QUAD(0);                                          /*0xFFFFFFE440000000*/
        QUAD(0);                                          /*0xFFFFFFE480000000*/
        QUAD(0);                                          /*0xFFFFFFE4C0000000*/
        QUAD(0);                                          /*0xFFFFFFE500000000*/
        QUAD(0);                                          /*0xFFFFFFE540000000*/
        QUAD(0);                                          /*0xFFFFFFE580000000*/
        QUAD(0);                                          /*0xFFFFFFE5C0000000*/
        QUAD(0);                                          /*0xFFFFFFE600000000*/
        QUAD(0);                                          /*0xFFFFFFE640000000*/
        QUAD(0);                                          /*0xFFFFFFE680000000*/
        QUAD(0);                                          /*0xFFFFFFE6C0000000*/
        QUAD(0);                                          /*0xFFFFFFE700000000*/
        QUAD(0);                                          /*0xFFFFFFE740000000*/
        QUAD(0);                                          /*0xFFFFFFE780000000*/
        QUAD(0);                                          /*0xFFFFFFE7C0000000*/
        QUAD(0);                                          /*0xFFFFFFE800000000*/
        QUAD(0);                                          /*0xFFFFFFE840000000*/
        QUAD(0);                                          /*0xFFFFFFE880000000*/
        QUAD(0);                                          /*0xFFFFFFE8C0000000*/
        QUAD(0);                                          /*0xFFFFFFE900000000*/
        QUAD(0);                                          /*0xFFFFFFE940000000*/
        QUAD(0);                                          /*0xFFFFFFE980000000*/
        QUAD(0);                                          /*0xFFFFFFE9C0000000*/
        QUAD(0);                                          /*0xFFFFFFEA00000000*/
        QUAD(0);                                          /*0xFFFFFFEA40000000*/
        QUAD(0);                                          /*0xFFFFFFEA80000000*/
        QUAD(0);                                          /*0xFFFFFFEAC0000000*/
        QUAD(0);                                          /*0xFFFFFFEB00000000*/
        QUAD(0);                                          /*0xFFFFFFEB40000000*/
        QUAD(0);                                          /*0xFFFFFFEB80000000*/
        QUAD(0);                                          /*0xFFFFFFEBC0000000*/
        QUAD(0);                                          /*0xFFFFFFEC00000000*/
        QUAD(0);                                          /*0xFFFFFFEC40000000*/
        QUAD(0);                                          /*0xFFFFFFEC80000000*/
        QUAD(0);                                          /*0xFFFFFFECC0000000*/
        QUAD(0);                                          /*0xFFFFFFED00000000*/
        QUAD(0);                                          /*0xFFFFFFED40000000*/
        QUAD(0);                                          /*0xFFFFFFED80000000*/
        QUAD(0);                                          /*0xFFFFFFEDC0000000*/
        QUAD(0);                                          /*0xFFFFFFEE00000000*/
        QUAD(0);                                          /*0xFFFFFFEE40000000*/
        QUAD(0);                                          /*0xFFFFFFEE80000000*/
        QUAD(0);                                          /*0xFFFFFFEEC0000000*/
        QUAD(0);                                          /*0xFFFFFFEF00000000*/
        QUAD(0);                                          /*0xFFFFFFEF40000000*/
        QUAD(0);                                          /*0xFFFFFFEF80000000*/
        QUAD(0);                                          /*0xFFFFFFEFC0000000*/
        QUAD(0);                                          /*0xFFFFFFF000000000*/
        QUAD(0);                                          /*0xFFFFFFF040000000*/
        QUAD(0);                                          /*0xFFFFFFF080000000*/
        QUAD(0);                                          /*0xFFFFFFF0C0000000*/
        QUAD(0);                                          /*0xFFFFFFF100000000*/
        QUAD(0);                                          /*0xFFFFFFF140000000*/
        QUAD(0);                                          /*0xFFFFFFF180000000*/
        QUAD(0);                                          /*0xFFFFFFF1C0000000*/
        QUAD(0);                                          /*0xFFFFFFF200000000*/
        QUAD(0);                                          /*0xFFFFFFF240000000*/
        QUAD(0);                                          /*0xFFFFFFF280000000*/
        QUAD(0);                                          /*0xFFFFFFF2C0000000*/
        QUAD(0);                                          /*0xFFFFFFF300000000*/
        QUAD(0);                                          /*0xFFFFFFF340000000*/
        QUAD(0);                                          /*0xFFFFFFF380000000*/
        QUAD(0);                                          /*0xFFFFFFF3C0000000*/
        QUAD(0);                                          /*0xFFFFFFF400000000*/
        QUAD(0);                                          /*0xFFFFFFF440000000*/
        QUAD(0);                                          /*0xFFFFFFF480000000*/
        QUAD(0);                                          /*0xFFFFFFF4C0000000*/
        QUAD(0);                                          /*0xFFFFFFF500000000*/
        QUAD(0);                                          /*0xFFFFFFF540000000*/
        QUAD(0);                                          /*0xFFFFFFF580000000*/
        QUAD(0);                                          /*0xFFFFFFF5C0000000*/
        QUAD(0);                                          /*0xFFFFFFF600000000*/
        QUAD(0);                                          /*0xFFFFFFF640000000*/
        QUAD(0);                                          /*0xFFFFFFF680000000*/
        QUAD(0);                                          /*0xFFFFFFF6C0000000*/
        QUAD(0);                                          /*0xFFFFFFF700000000*/
        QUAD(0);                                          /*0xFFFFFFF740000000*/
        QUAD(0);                                          /*0xFFFFFFF780000000*/
        QUAD(0);                                          /*0xFFFFFFF7C0000000*/
        QUAD(0);                                          /*0xFFFFFFF800000000*/
        QUAD(0);                                          /*0xFFFFFFF840000000*/
        QUAD(0);                                          /*0xFFFFFFF880000000*/
        QUAD(0);                                          /*0xFFFFFFF8C0000000*/
        QUAD(0);                                          /*0xFFFFFFF900000000*/
        QUAD(0);                                          /*0xFFFFFFF940000000*/
        QUAD(0);                                          /*0xFFFFFFF980000000*/
        QUAD(0);                                          /*0xFFFFFFF9C0000000*/
        QUAD(0);                                          /*0xFFFFFFFA00000000*/
        QUAD(0);                                          /*0xFFFFFFFA40000000*/
        QUAD(0);                                          /*0xFFFFFFFA80000000*/
        QUAD(0);                                          /*0xFFFFFFFAC0000000*/
        QUAD(0);                                          /*0xFFFFFFFB00000000*/
        QUAD(0);                                          /*0xFFFFFFFB40000000*/
        QUAD(0);                                          /*0xFFFFFFFB80000000*/
        QUAD(0);                                          /*0xFFFFFFFBC0000000*/
        QUAD(0);                                          /*0xFFFFFFFC00000000*/
        QUAD(0);                                          /*0xFFFFFFFC40000000*/
        QUAD(0);                                          /*0xFFFFFFFC80000000*/
        QUAD(0);                                          /*0xFFFFFFFCC0000000*/
        QUAD(0);                                          /*0xFFFFFFFD00000000*/
        QUAD(0);                                          /*0xFFFFFFFD40000000*/
        QUAD(0);                                          /*0xFFFFFFFD80000000*/
        QUAD(0);                                          /*0xFFFFFFFDC0000000*/
        QUAD(0);                                          /*0xFFFFFFFE00000000*/
        QUAD(0);                                          /*0xFFFFFFFE40000000*/
        QUAD(0);                                          /*0xFFFFFFFE80000000*/
        QUAD(0);                                          /*0xFFFFFFFEC0000000*/
        QUAD(0);                                          /*0xFFFFFFFF00000000*/
        QUAD(0);                                          /*0xFFFFFFFF40000000*/
        QUAD(0);                                          /*0xFFFFFFFF80000000*/
        QUAD((_page_table + 0x2000) | 0x1000000000000003);/*0xFFFFFFFFC0000000*/

        . = ALIGN(4096);
    }

    ASSERT((. - _virt_addr) % 512 == 0, "not an integral number of sectors")
    _num_sectors = (. - _virt_addr) / 512;
    _sbrk = . - _virt_addr + _phys_addr;
}
